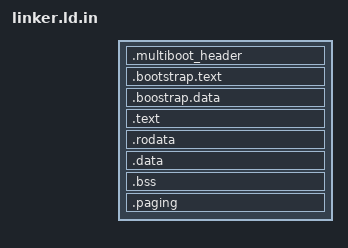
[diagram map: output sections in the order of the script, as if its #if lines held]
/*
 * Copyright (C) 2018 Jake Shilling <shilling.jake@gmail.com>
 *
 * This program is free software: you can redistribute it and/or modify
 * it under the terms of the GNU General Public License as published by
 * the Free Software Foundation, either version 3 of the License, or
 * (at your option) any later version.
 *
 * This program is distributed in the hope that it will be useful,
 * but WITHOUT ANY WARRANTY; without even the implied warranty of
 * MERCHANTABILITY or FITNESS FOR A PARTICULAR PURPOSE.  See the
 * GNU General Public License for more details.
 *
 * You should have received a copy of the GNU General Public License
 * along with this program.  If not, see <http://www.gnu.org/licenses/>.
 */
 
#include <arch/cdefs.h>

#if __x86_64__
#  define FORMAT  "elf64-x86-64"
#else
#  define FORMAT  "elf32-i386"
#endif /* __x86_64__ */

#define ASM_FILE 1
#include <multiboot.h>
#define MULTIBOOT_HEADER_FLAGS \
  (MULTIBOOT_PAGE_ALIGN | MULTIBOOT_MEMORY_INFO | MULTIBOOT_VIDEO_MODE)

OUTPUT_FORMAT(FORMAT)
ENTRY(_start)

mb_magic = MULTIBOOT_HEADER_MAGIC;
mb_flags = MULTIBOOT_HEADER_FLAGS;
mb_checksum = -(mb_magic + mb_flags);

SECTIONS {

  . = KERNEL_LMA;
  _kernel_start = . + KERNEL_VBASE;

  .multiboot_header :
  {
    . = ALIGN(16);
    LONG(mb_magic);
    LONG(mb_flags);
    LONG(mb_checksum);
  }

  .bootstrap.text ALIGN(4K) :
  {
      *(.bootstrap.text)
  }

  .boostrap.data ALIGN(4K) :
  {
      *(.bootstrap.data)
  }

  . += KERNEL_VBASE;

  .text ALIGN(4K): AT(ADDR(.text) - KERNEL_VBASE)
  {
    *(.text)
  }

  .rodata ALIGN(4K): AT(ADDR(.rodata) - KERNEL_VBASE)
  {
    *(.rodata)
  }

  .data ALIGN(4K): AT(ADDR(.data) - KERNEL_VBASE)
  {
    *(.data)
  }

  .bss ALIGN(4K): AT(ADDR(.bss) - KERNEL_VBASE)
  {
    *(COMMON)
    *(.bss)
  }

  _kernel_end = .;
  kernel_size = _kernel_end - _kernel_start;

  .paging ALIGN(4K): AT(ADDR(.paging) - KERNEL_VBASE)
  {
    /* We need enough page tables for the entire kernel twice. Each page
     * has 1024 entries pointing to 4086 bytes of space. */
#define N_PAGE_TABLES (2 * (1 + (kernel_size / (1024 * 4086))))
    /* We now need enough page directories to hole all of our page tables */
#define N_PAGE_DIRS   (1 + (N_PAGE_TABLES / 1024))

    initial_page_tables = .;
    . += 4096 * N_PAGE_TABLES;
    initial_page_directories = .;
    . += 4096 * N_PAGE_DIRS;

#if __x86_86__

    /* In 64-bit paging we also need page directory pointers and a PML4 */
#define N_PAGE_DIR_PTRS (1 + (N_PAGE_DIRS / 1024))
#define N_PML4          (1 + (N_PAGE_DIR_PTRS))

    initial_page_director_pointers = .;
    . += 4096 * N_PAGE_DIR_PTRS;
    initial_pml4 = .;
    . += 4096 * N_PML4;

#endif 
  }
}
